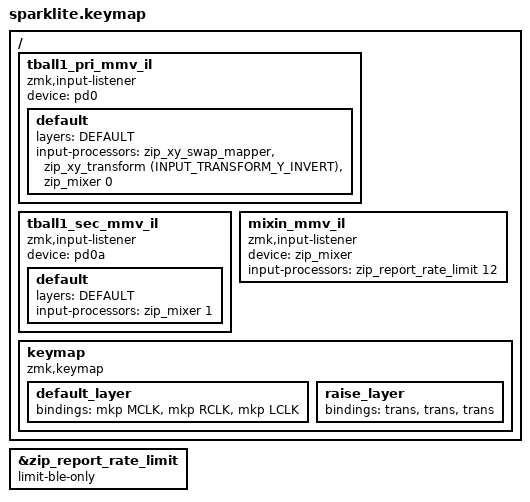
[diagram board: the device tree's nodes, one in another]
/*
 * Copyright (c) 2020 The ZMK Contributors
 *
 * SPDX-License-Identifier: MIT
 */

#include <zephyr/dt-bindings/input/input-event-codes.h>

#include <behaviors.dtsi>
// #include <behaviors/mouse_keys.dtsi>
#include <behaviors/mouse_key_press.dtsi>
#include <behaviors/mouse_key_toggle.dtsi>
#include <dt-bindings/zmk/keys.h>
#include <dt-bindings/zmk/bt.h>
#include <dt-bindings/zmk/rgb.h>
#include <dt-bindings/zmk/ext_power.h>
#include <dt-bindings/zmk/outputs.h>
#include <dt-bindings/zmk/mouse.h>
#include <dt-bindings/zmk/input_transform.h>
#include <input/processors.dtsi>

#include <input/processors/mixer.dtsi>
#include <input/processors/report_rate_limit.dtsi>

#define DEFAULT 0
#define RAISE   1

// #define OUTPUT_SOURCE_LAYER_STATE_CHANGE        1
// #define OUTPUT_SOURCE_POSITION_STATE_CHANGE     2
// #define OUTPUT_SOURCE_KEYCODE_STATE_CHANGE      3
// #define OUTPUT_SOURCE_TRANSPORT                 4

&zip_report_rate_limit {
        limit-ble-only;
};

/ {
        tball1_pri_mmv_il {
                compatible = "zmk,input-listener";
                device = <&pd0>;
                default {
                        layers = <DEFAULT>;
                        // sensor at 6 o'clock pos
                        input-processors = <&zip_xy_swap_mapper>
                                         , <&zip_xy_transform (INPUT_TRANSFORM_Y_INVERT)>
                                         , <&zip_mixer 0>;
                };
        };
        tball1_sec_mmv_il {
                compatible = "zmk,input-listener";
                device = <&pd0a>;
                default {
                        layers = <DEFAULT>;
                        // sensor at 3 o'clock pos
                        input-processors = <&zip_mixer 1>;
                };
        };
        mixin_mmv_il {
                compatible = "zmk,input-listener";
                device = <&zip_mixer>;
                input-processors = <&zip_report_rate_limit 12>;
        };

        // tball1_mmv_il {
        //         compatible = "zmk,input-listener";
        //         device = <&pd0>;
        //         default {
        //                 layers = <DEFAULT>;
        //                 // input-processors 
        //                 //         = <&zip_xy_swap_mapper>
        //                 //         , <&zip_xy_transform (INPUT_TRANSFORM_X_INVERT)>
        //                 //         ;
        //         };
        // };

        // tball2_mmv_il {
        //         compatible = "zmk,input-listener";
        //         device = <&pd0i>;
        //         default {
        //                 layers = <DEFAULT>;
        //         };
        // };

        // tpad0_mmv_il {
        //         compatible = "zmk,input-listener";
        //         device = <&tpad0>;
        //         default {
        //                 layers = <DEFAULT>;
        //         };
        // };

        // erm0_obl__enter_raise_layer {
        //         compatible = "zmk,output-behavior-listener";
        //         layers = < RAISE >;
        //         sources = < OUTPUT_SOURCE_LAYER_STATE_CHANGE >;
        //         bindings = < &ob_erm0_in &ob_erm0_out >;
        // };
        // erm0_obl__back_to_default_layer {
        //         compatible = "zmk,output-behavior-listener";
        //         layers = < DEFAULT >;
        //         sources = < OUTPUT_SOURCE_LAYER_STATE_CHANGE >;
        //         invert-state;
        //         bindings = < &ob_erm0_out >;
        // };
        // erm0_obl__press_position_5 {
        //         compatible = "zmk,output-behavior-listener";
        //         layers = < DEFAULT >;
        //         sources = < OUTPUT_SOURCE_POSITION_STATE_CHANGE >;
        //         position = <5>;
        //         bindings = < &ob_erm0_in >;
        // };
        // erm0_obl__press_key_code_D {
        //         compatible = "zmk,output-behavior-listener";
        //         layers = < DEFAULT >;
        //         sources = < OUTPUT_SOURCE_KEYCODE_STATE_CHANGE >;
        //         position = < 0x07 >;
        //         bindings = < &ob_erm0_in >;
        // };
        // ob_erm0_in: ob_generic_erm0_in {
        //         compatible = "zmk,output-behavior-generic"; #binding-cells = <0>;
        //         device = <&lra0>; delay = <1>; time-to-live-ms = <30>; force = <80>;
        // };
        // ob_erm0_out: ob_generic_erm0_out {
        //         compatible = "zmk,output-behavior-generic"; #binding-cells = <0>;
        //         device = <&lra0>; delay = <133>; time-to-live-ms = <10>; force = <30>;
        // };

        keymap {
                compatible = "zmk,keymap";
                default_layer {
                        bindings = <
//    &bt BT_CLR   &out OUT_TOG      &mkp LCLK   &mkp RCLK
//    &mkp LCLK    &mo RAISE         &mkp MCLK   &mktg MB4
&mkp MCLK   &mkp RCLK   &mkp LCLK
                        >;
                };
                raise_layer {
                        bindings = <
//    &trans       &trans            &trans       &trans
//    &trans       &trans            &trans       &trans
&trans       &trans       &trans
                        >;
                };
       };
};
